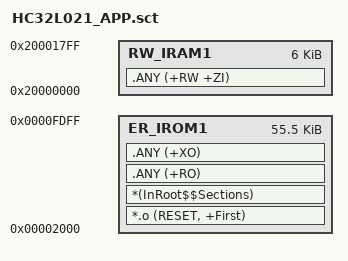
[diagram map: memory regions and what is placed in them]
; *************************************************************
; *** Scatter-Loading Description File for APP (bootloadable) ***
; *** 基地址：0x00002000，最大 0xDE00 字节（~55.5KB）      ***
; *************************************************************

LR_IROM1 0x00002000 0x0000DE00  {    ; load region size_region
  ER_IROM1 0x00002000 0x0000DE00  {  ; load address = execution address
   *.o (RESET, +First)
   *(InRoot$$Sections)
   .ANY (+RO)
   .ANY (+XO)
  }
  RW_IRAM1 0x20000000 0x00001800  {  ; RW data
   .ANY (+RW +ZI)
  }
}
